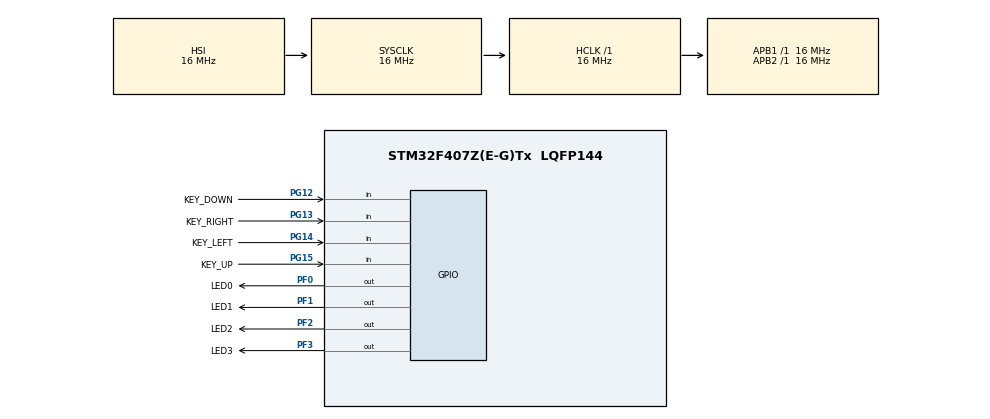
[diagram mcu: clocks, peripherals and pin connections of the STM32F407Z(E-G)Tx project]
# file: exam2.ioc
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Mcu.Family=STM32F4
Mcu.Name=STM32F407Z(E-G)Tx
Mcu.Package=LQFP144
NVIC.PriorityGroup=NVIC_PRIORITYGROUP_4
PF0.GPIO_Label=LED0
PF0.GPIO_ModeDefaultOutputPP=GPIO_MODE_OUTPUT_PP
PF0.GPIO_PuPd=GPIO_NOPULL
PF0.GPIO_Speed=GPIO_SPEED_FREQ_LOW
PF0.PinState=GPIO_PIN_SET
PF0.Signal=GPIO_Output
PF1.GPIO_Label=LED1
PF1.GPIO_ModeDefaultOutputPP=GPIO_MODE_OUTPUT_PP
PF1.GPIO_PuPd=GPIO_NOPULL
PF1.GPIO_Speed=GPIO_SPEED_FREQ_LOW
PF1.PinState=GPIO_PIN_SET
PF1.Signal=GPIO_Output
PF2.GPIO_Label=LED2
PF2.GPIO_ModeDefaultOutputPP=GPIO_MODE_OUTPUT_PP
PF2.GPIO_PuPd=GPIO_NOPULL
PF2.GPIO_Speed=GPIO_SPEED_FREQ_LOW
PF2.PinState=GPIO_PIN_SET
PF2.Signal=GPIO_Output
PF3.GPIO_Label=LED3
PF3.GPIO_ModeDefaultOutputPP=GPIO_MODE_OUTPUT_PP
PF3.GPIO_PuPd=GPIO_NOPULL
PF3.GPIO_Speed=GPIO_SPEED_FREQ_LOW
PF3.PinState=GPIO_PIN_SET
PF3.Signal=GPIO_Output
PG12.GPIO_Label=KEY_DOWN
PG12.Signal=GPIO_Input
PG13.GPIO_Label=KEY_RIGHT
PG13.Signal=GPIO_Input
PG14.GPIO_Label=KEY_LEFT
PG14.Signal=GPIO_Input
PG15.GPIO_Label=KEY_UP
PG15.Signal=GPIO_Input
PH0-OSC_IN.Mode=HSE-External-Oscillator
PH0-OSC_IN.Signal=RCC_OSC_IN
PH1-OSC_OUT.Mode=HSE-External-Oscillator
PH1-OSC_OUT.Signal=RCC_OSC_OUT
ProjectManager.HeapSize=0x200
ProjectManager.StackSize=0x400
ProjectManager.TargetToolchain=MDK-ARM V5
RCC.AHBFreq_Value=16000000
RCC.APB1Freq_Value=16000000
RCC.APB2Freq_Value=16000000
RCC.CortexFreq_Value=16000000
RCC.HSE_VALUE=25000000
RCC.HSI_VALUE=16000000
RCC.LSE_VALUE=32768
RCC.SYSCLKFreq_VALUE=16000000
RCC.VCOOutputFreq_Value=192000000
board=custom

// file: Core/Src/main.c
/* USER CODE BEGIN Header */
/**
  ******************************************************************************
  * @file           : main.c
  * @brief          : Main program body
  ******************************************************************************
  * @attention
  *
  * Copyright (c) 2022 STMicroelectronics.
  * All rights reserved.
  *
  * This software is licensed under terms that can be found in the LICENSE file
  * in the root directory of this software component.
  * If no LICENSE file comes with this software, it is provided AS-IS.
  *
  ******************************************************************************
  */
/* USER CODE END Header */
#include "main.h"

void SystemClock_Config(void);
static void MX_GPIO_Init(void);
/* USER CODE BEGIN PFP */
int check(GPIO_TypeDef* GPIOx, uint16_t GPIO_Pin);
/* USER CODE END PFP */

int main(void)
{

  /* MCU Configuration--------------------------------------------------------*/

  /* Reset of all peripherals, Initializes the Flash interface and the Systick. */
  HAL_Init();

  /* Configure the system clock */
  SystemClock_Config();

  /* Initialize all configured peripherals */
  MX_GPIO_Init();

  /* Infinite loop */
  while (1)
  {
		if(check(KEY_LEFT_GPIO_Port,KEY_LEFT_Pin)==1){
			HAL_GPIO_WritePin(LED0_GPIO_Port,LED0_Pin,GPIO_PIN_RESET);
			HAL_GPIO_WritePin(LED1_GPIO_Port,LED1_Pin,GPIO_PIN_SET);
			HAL_GPIO_WritePin(LED2_GPIO_Port,LED2_Pin,GPIO_PIN_SET);
			HAL_GPIO_WritePin(LED3_GPIO_Port,LED3_Pin,GPIO_PIN_SET);
		}
		else if(check(KEY_RIGHT_GPIO_Port,KEY_RIGHT_Pin)==1){
			HAL_GPIO_WritePin(LED0_GPIO_Port,LED0_Pin,GPIO_PIN_SET);
			HAL_GPIO_WritePin(LED1_GPIO_Port,LED1_Pin,GPIO_PIN_RESET);
			HAL_GPIO_WritePin(LED2_GPIO_Port,LED2_Pin,GPIO_PIN_SET);
			HAL_GPIO_WritePin(LED3_GPIO_Port,LED3_Pin,GPIO_PIN_SET);
		}
		else if(check(KEY_UP_GPIO_Port,KEY_UP_Pin)==1){
			HAL_GPIO_WritePin(LED0_GPIO_Port,LED0_Pin,GPIO_PIN_SET);
			HAL_GPIO_WritePin(LED1_GPIO_Port,LED1_Pin,GPIO_PIN_SET);
			HAL_GPIO_WritePin(LED2_GPIO_Port,LED2_Pin,GPIO_PIN_RESET);
			HAL_GPIO_WritePin(LED3_GPIO_Port,LED3_Pin,GPIO_PIN_SET);
		}
		else if(check(KEY_DOWN_GPIO_Port,KEY_DOWN_Pin)==1){
			HAL_GPIO_WritePin(LED0_GPIO_Port,LED0_Pin,GPIO_PIN_SET);
			HAL_GPIO_WritePin(LED1_GPIO_Port,LED1_Pin,GPIO_PIN_SET);
			HAL_GPIO_WritePin(LED2_GPIO_Port,LED2_Pin,GPIO_PIN_SET);
			HAL_GPIO_WritePin(LED3_GPIO_Port,LED3_Pin,GPIO_PIN_RESET);
		}
		else{
			HAL_GPIO_WritePin(LED0_GPIO_Port,LED0_Pin,GPIO_PIN_SET);
			HAL_GPIO_WritePin(LED1_GPIO_Port,LED1_Pin,GPIO_PIN_SET);
			HAL_GPIO_WritePin(LED2_GPIO_Port,LED2_Pin,GPIO_PIN_SET);
			HAL_GPIO_WritePin(LED3_GPIO_Port,LED3_Pin,GPIO_PIN_SET);
		}
  }
}
int check(GPIO_TypeDef* GPIOx, uint16_t GPIO_Pin){
	if(HAL_GPIO_ReadPin(GPIOx,GPIO_Pin)==GPIO_PIN_RESET){
		HAL_Delay(8);
		if(HAL_GPIO_ReadPin(GPIOx,GPIO_Pin)==GPIO_PIN_RESET){
			return 1;
		}
		else{
			return 0;
		}
	}
	else return 0;
}

void SystemClock_Config(void)
{
  RCC_OscInitTypeDef RCC_OscInitStruct = {0};
  RCC_ClkInitTypeDef RCC_ClkInitStruct = {0};

  /** Configure the main internal regulator output voltage
  */
  __HAL_RCC_PWR_CLK_ENABLE();
  __HAL_PWR_VOLTAGESCALING_CONFIG(PWR_REGULATOR_VOLTAGE_SCALE1);

  /** Initializes the RCC Oscillators according to the specified parameters
  * in the RCC_OscInitTypeDef structure.
  */
  RCC_OscInitStruct.OscillatorType = RCC_OSCILLATORTYPE_HSI;
  RCC_OscInitStruct.HSIState = RCC_HSI_ON;
  RCC_OscInitStruct.HSICalibrationValue = RCC_HSICALIBRATION_DEFAULT;
  RCC_OscInitStruct.PLL.PLLState = RCC_PLL_NONE;
  if (HAL_RCC_OscConfig(&RCC_OscInitStruct) != HAL_OK)
  {
    Error_Handler();
  }

  /** Initializes the CPU, AHB and APB buses clocks
  */
  RCC_ClkInitStruct.ClockType = RCC_CLOCKTYPE_HCLK|RCC_CLOCKTYPE_SYSCLK
                              |RCC_CLOCKTYPE_PCLK1|RCC_CLOCKTYPE_PCLK2;
  RCC_ClkInitStruct.SYSCLKSource = RCC_SYSCLKSOURCE_HSI;
  RCC_ClkInitStruct.AHBCLKDivider = RCC_SYSCLK_DIV1;
  RCC_ClkInitStruct.APB1CLKDivider = RCC_HCLK_DIV1;
  RCC_ClkInitStruct.APB2CLKDivider = RCC_HCLK_DIV1;

  if (HAL_RCC_ClockConfig(&RCC_ClkInitStruct, FLASH_LATENCY_0) != HAL_OK)
  {
    Error_Handler();
  }
}

static void MX_GPIO_Init(void)
{
  GPIO_InitTypeDef GPIO_InitStruct = {0};

  /* GPIO Ports Clock Enable */
  __HAL_RCC_GPIOF_CLK_ENABLE();
  __HAL_RCC_GPIOH_CLK_ENABLE();
  __HAL_RCC_GPIOG_CLK_ENABLE();

  /*Configure GPIO pin Output Level */
  HAL_GPIO_WritePin(GPIOF, GPIO_PIN_0|GPIO_PIN_1|GPIO_PIN_2|GPIO_PIN_3, GPIO_PIN_SET);

  /*Configure GPIO pins : PF0 PF1 PF2 PF3 */
  GPIO_InitStruct.Pin = GPIO_PIN_0|GPIO_PIN_1|GPIO_PIN_2|GPIO_PIN_3;
  GPIO_InitStruct.Mode = GPIO_MODE_OUTPUT_PP;
  GPIO_InitStruct.Pull = GPIO_NOPULL;
  GPIO_InitStruct.Speed = GPIO_SPEED_FREQ_LOW;
  HAL_GPIO_Init(GPIOF, &GPIO_InitStruct);

  /*Configure GPIO pins : PG12 PG13 PG14 PG15 */
  GPIO_InitStruct.Pin = GPIO_PIN_12|GPIO_PIN_13|GPIO_PIN_14|GPIO_PIN_15;
  GPIO_InitStruct.Mode = GPIO_MODE_INPUT;
  GPIO_InitStruct.Pull = GPIO_NOPULL;
  HAL_GPIO_Init(GPIOG, &GPIO_InitStruct);

}

void Error_Handler(void)
{
  __disable_irq();
  while (1)
  {
  }
}
